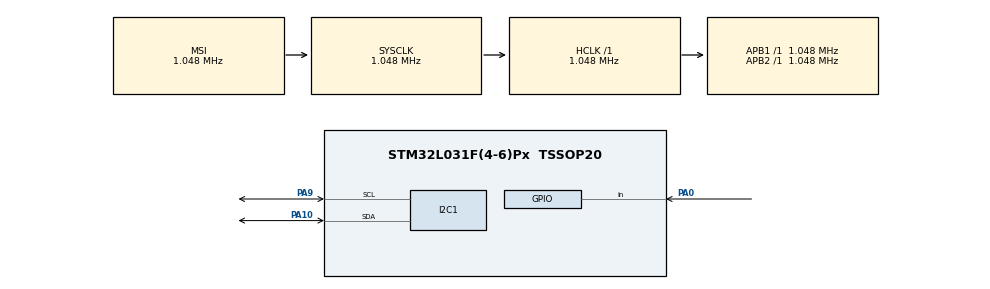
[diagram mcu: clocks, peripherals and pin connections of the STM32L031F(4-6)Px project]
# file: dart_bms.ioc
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I2C1.I2C_Coeff_DF=7
I2C1.I2C_Fall_Time=200
I2C1.I2C_Rise_Time=1000
I2C1.SMBusOwnAddress=12
I2C1.Speed=100
I2C1.Timeout=0x0000800C
I2C1.Timing=0x00000000
Mcu.Family=STM32L0
Mcu.Name=STM32L031F(4-6)Px
Mcu.Package=TSSOP20
NVIC.I2C1_IRQn=true\:0\:0\:false\:false\:true\:true\:true\:true
NVIC.TIM2_IRQn=true\:0\:0\:false\:false\:true\:true\:true\:true
PA0-CK_IN.Signal=GPIO_Input
PA10.Mode=SMBus-two-wire-Interface
PA10.Signal=I2C1_SDA
PA13.Mode=Serial_Wire
PA13.Signal=SYS_SWDIO
PA14.Mode=Serial_Wire
PA14.Signal=SYS_SWCLK
PA9.GPIO_Pu=GPIO_NOPULL
PA9.Mode=SMBus-two-wire-Interface
PA9.Signal=I2C1_SCL
PC14-OSC32_IN.Mode=LSE-External-Oscillator
PC14-OSC32_IN.Signal=RCC_OSC32_IN
PC15-OSC32_OUT.Mode=LSE-External-Oscillator
PC15-OSC32_OUT.Signal=RCC_OSC32_OUT
ProjectManager.HeapSize=0x200
ProjectManager.StackSize=0x400
ProjectManager.TargetToolchain=STM32CubeIDE
RCC.AHBFreq_Value=1048000
RCC.APB1Freq_Value=1048000
RCC.APB1TimFreq_Value=1048000
RCC.APB2Freq_Value=1048000
RCC.APB2TimFreq_Value=1048000
RCC.HCLKFreq_Value=1048000
RCC.HSE_VALUE=8000000
RCC.HSI16_VALUE=16000000
RCC.HSI_VALUE=16000000
RCC.MSIClockRange=RCC_MSIRANGE_4
RCC.MSI_VALUE=1048000
RCC.SYSCLKFreq_VALUE=1048000
RCC.VCOOutputFreq_Value=48000000
TIM2.ClockDivision=TIM_CLOCKDIVISION_DIV4
TIM2.Period=2620
VP_SYS_VS_LPOM.Mode=PowerOptimisation
VP_TIM2_VS_ClockSourceINT.Mode=Internal
board=custom

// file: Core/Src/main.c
/* USER CODE BEGIN Header */
/**
  ******************************************************************************
  * @file           : main.c
  * @brief          : Main program body
  ******************************************************************************
  * @attention
  *
  * Copyright (c) 2024 STMicroelectronics.
  * All rights reserved.
  *
  * This software is licensed under terms that can be found in the LICENSE file
  * in the root directory of this software component.
  * If no LICENSE file comes with this software, it is provided AS-IS.
  *
  ******************************************************************************
  */
/* USER CODE END Header */
#include "main.h"

/* USER CODE BEGIN Includes */
#include "chalie_leds.h"
/* USER CODE END Includes */

SMBUS_HandleTypeDef hsmbus1;

TIM_HandleTypeDef htim2;

void SystemClock_Config(void);

static void MX_GPIO_Init(void);

static void MX_TIM2_Init(void);

static void MX_I2C1_SMBUS_Init(void);

int main(void) {

    /* MCU Configuration--------------------------------------------------------*/

    /* Reset of all peripherals, Initializes the Flash interface and the Systick. */
    HAL_Init();

    /* Configure the system clock */
    SystemClock_Config();

    /* Initialize all configured peripherals */
    MX_GPIO_Init();
    MX_TIM2_Init();
    MX_I2C1_SMBUS_Init();
    /* USER CODE BEGIN 2 */
    chalie_leds_init();
    HAL_SMBUS_EnableListen_IT(&hsmbus1);
    /* USER CODE END 2 */

    /* Infinite loop */
    /* USER CODE BEGIN WHILE */
    int code = 0;
    uint8_t soc = 0;
    uint8_t address = 0x17;
    uint8_t soc_address = 0x0d;
    uint8_t read = 0;
    uint8_t current_address = 0x0a;
    int16_t current = 0;
    uint8_t last_timer_it_state = 0;
    uint8_t DSG_address = 0x0020;
    uint8_t CHG_address = 0x001F;
    uint8_t PCHG_address = 0x001E;
    uint8_t button_state_machine = 0;
    enum {
        BUTTON_STATE_IDLE = 0,
        BUTTON_STATE_SHORT_PRESS = 1,
        BUTTON_STATE_L
    };

    // 启动DSG，CHG，PCHG
    while (1) {
        /* USER CODE END WHILE */

        /* USER CODE BEGIN 3 */
        // SMBUS 读取0x0D寄存器 State of Charge，格式WORD
        if (HAL_GetTick() % 1000 > 500 && !read) {
            // HAL_I2C_Master_Transmit(&hi2c1, address, (uint8_t *) &soc_address, 1, 100);
            // HAL_I2C_Master_Receive(&hi2c1, address, (uint8_t *) &soc, 1, 100);
            // HAL_I2C_Master_Transmit(&hi2c1, address, (uint8_t *) &current_address, 1, 100);
            // HAL_I2C_Master_Receive(&hi2c1, address, (uint8_t *) &current, 2, 100);

            read = 1;
            // 将SOC0～100转换到0-7的范围
            code = soc / 12.5 + 1;
        } else if (HAL_GetTick() % 1000 < 500) {
            read = 0;
        }

        // 如果PA0被按下，LED显示SOC
        if (HAL_GPIO_ReadPin(GPIOA, GPIO_PIN_0) == GPIO_PIN_RESET) {
            if (!last_timer_it_state) {
                HAL_TIM_Base_Start_IT(&htim2);
                last_timer_it_state = 1;
                chalie_leds_set(1, GPIO_PIN_RESET);
                for (int i = 1; i < code; i += 2) {
                    chalie_led_code(i);
                    HAL_Delay(100);
                }
                chalie_led_code(code);
            }

            HAL_Delay(3000);
            HAL_TIM_Base_Stop_IT(&htim2);
            last_timer_it_state = 0;
            chalie_led_timer_update(1);
            chalie_leds_set(1, GPIO_PIN_RESET);
        } else if (current > 50 || current < -100) {
            if (!last_timer_it_state) {
                HAL_TIM_Base_Start_IT(&htim2);
                last_timer_it_state = 1;
                chalie_leds_set(1, GPIO_PIN_RESET);
                for (int i = 1; i < code; i += 2) {
                    chalie_led_code(i);
                    HAL_Delay(100);
                }
                chalie_led_code(code);
            }
            chalie_led_code(code);
            HAL_Delay(10);
        } else {
            if (last_timer_it_state) {
                HAL_TIM_Base_Stop_IT(&htim2);
                last_timer_it_state = 0;
                chalie_led_timer_update(1);
                chalie_leds_set(1, GPIO_PIN_RESET);
            }

            HAL_Delay(10);
        }
    }
    /* USER CODE END 3 */
}

void SystemClock_Config(void) {
    RCC_OscInitTypeDef RCC_OscInitStruct = {0};
    RCC_ClkInitTypeDef RCC_ClkInitStruct = {0};
    RCC_PeriphCLKInitTypeDef PeriphClkInit = {0};

    /** Configure the main internal regulator output voltage
    */
    __HAL_PWR_VOLTAGESCALING_CONFIG(PWR_REGULATOR_VOLTAGE_SCALE1);

    /** Initializes the RCC Oscillators according to the specified parameters
    * in the RCC_OscInitTypeDef structure.
    */
    RCC_OscInitStruct.OscillatorType = RCC_OSCILLATORTYPE_MSI;
    RCC_OscInitStruct.MSIState = RCC_MSI_ON;
    RCC_OscInitStruct.MSICalibrationValue = 0;
    RCC_OscInitStruct.MSIClockRange = RCC_MSIRANGE_4;
    RCC_OscInitStruct.PLL.PLLState = RCC_PLL_NONE;
    if (HAL_RCC_OscConfig(&RCC_OscInitStruct) != HAL_OK) {
        Error_Handler();
    }

    /** Initializes the CPU, AHB and APB buses clocks
    */
    RCC_ClkInitStruct.ClockType = RCC_CLOCKTYPE_HCLK | RCC_CLOCKTYPE_SYSCLK
                                  | RCC_CLOCKTYPE_PCLK1 | RCC_CLOCKTYPE_PCLK2;
    RCC_ClkInitStruct.SYSCLKSource = RCC_SYSCLKSOURCE_MSI;
    RCC_ClkInitStruct.AHBCLKDivider = RCC_SYSCLK_DIV1;
    RCC_ClkInitStruct.APB1CLKDivider = RCC_HCLK_DIV1;
    RCC_ClkInitStruct.APB2CLKDivider = RCC_HCLK_DIV1;

    if (HAL_RCC_ClockConfig(&RCC_ClkInitStruct, FLASH_LATENCY_0) != HAL_OK) {
        Error_Handler();
    }
    PeriphClkInit.PeriphClockSelection = RCC_PERIPHCLK_I2C1;
    PeriphClkInit.I2c1ClockSelection = RCC_I2C1CLKSOURCE_PCLK1;
    if (HAL_RCCEx_PeriphCLKConfig(&PeriphClkInit) != HAL_OK) {
        Error_Handler();
    }
}

static void MX_I2C1_SMBUS_Init(void) {

    hsmbus1.Instance = I2C1;
    hsmbus1.Init.Timing = 0x00000000;
    hsmbus1.Init.AnalogFilter = SMBUS_ANALOGFILTER_ENABLE;
    hsmbus1.Init.OwnAddress1 = 24;
    hsmbus1.Init.AddressingMode = SMBUS_ADDRESSINGMODE_7BIT;
    hsmbus1.Init.DualAddressMode = SMBUS_DUALADDRESS_DISABLE;
    hsmbus1.Init.OwnAddress2 = 0;
    hsmbus1.Init.OwnAddress2Masks = SMBUS_OA2_NOMASK;
    hsmbus1.Init.GeneralCallMode = SMBUS_GENERALCALL_DISABLE;
    hsmbus1.Init.NoStretchMode = SMBUS_NOSTRETCH_DISABLE;
    hsmbus1.Init.PacketErrorCheckMode = SMBUS_PEC_DISABLE;
    hsmbus1.Init.PeripheralMode = SMBUS_PERIPHERAL_MODE_SMBUS_SLAVE;
    hsmbus1.Init.SMBusTimeout = 0x0000800C;
    if (HAL_SMBUS_Init(&hsmbus1) != HAL_OK) {
        Error_Handler();
    }
}

static void MX_TIM2_Init(void) {

    TIM_ClockConfigTypeDef sClockSourceConfig = {0};
    TIM_MasterConfigTypeDef sMasterConfig = {0};

    htim2.Instance = TIM2;
    htim2.Init.Prescaler = 0;
    htim2.Init.CounterMode = TIM_COUNTERMODE_UP;
    htim2.Init.Period = 2620;
    htim2.Init.ClockDivision = TIM_CLOCKDIVISION_DIV4;
    htim2.Init.AutoReloadPreload = TIM_AUTORELOAD_PRELOAD_DISABLE;
    if (HAL_TIM_Base_Init(&htim2) != HAL_OK) {
        Error_Handler();
    }
    sClockSourceConfig.ClockSource = TIM_CLOCKSOURCE_INTERNAL;
    if (HAL_TIM_ConfigClockSource(&htim2, &sClockSourceConfig) != HAL_OK) {
        Error_Handler();
    }
    sMasterConfig.MasterOutputTrigger = TIM_TRGO_RESET;
    sMasterConfig.MasterSlaveMode = TIM_MASTERSLAVEMODE_DISABLE;
    if (HAL_TIMEx_MasterConfigSynchronization(&htim2, &sMasterConfig) != HAL_OK) {
        Error_Handler();
    }
}

static void MX_GPIO_Init(void) {
    GPIO_InitTypeDef GPIO_InitStruct = {0};

    /* GPIO Ports Clock Enable */
    __HAL_RCC_GPIOC_CLK_ENABLE();
    __HAL_RCC_GPIOA_CLK_ENABLE();

    /*Configure GPIO pin : PA0 */
    GPIO_InitStruct.Pin = GPIO_PIN_0;
    GPIO_InitStruct.Mode = GPIO_MODE_INPUT;
    GPIO_InitStruct.Pull = GPIO_NOPULL;
    HAL_GPIO_Init(GPIOA, &GPIO_InitStruct);

}

/* USER CODE BEGIN 4 */
void HAL_TIM_PeriodElapsedCallback(TIM_HandleTypeDef *htim) {
    if (htim == &htim2)
        chalie_led_timer_update(0);
}

void HAL_SMBUS_AddrCallback(SMBUS_HandleTypeDef *hsmbus, uint8_t TransferDirection, uint16_t AddrMatchCode) {

}

/* USER CODE END 4 */

void Error_Handler(void) {
    __disable_irq();
    while (1) {
    }
}
